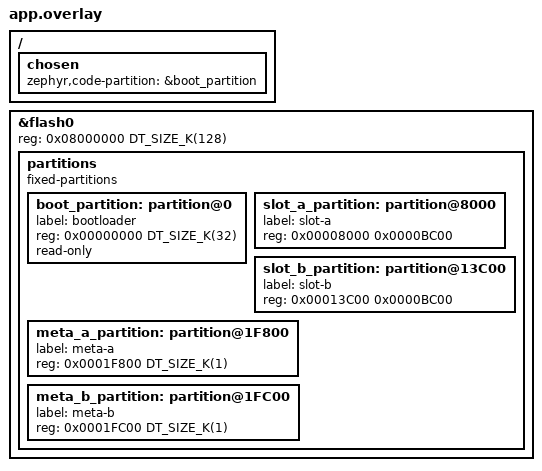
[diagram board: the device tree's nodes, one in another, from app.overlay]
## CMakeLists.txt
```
cmake_minimum_required(VERSION 3.20.0)

find_package(Zephyr REQUIRED HINTS $ENV{ZEPHYR_BASE})
project(f103_usb_bootloader)

target_sources(app PRIVATE
  src/main.c
  src/flash_update.c
  common/f103_bootloader_api.c
)

target_include_directories(app PRIVATE
  include
  src
  common
)
```

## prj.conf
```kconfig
CONFIG_MAIN_STACK_SIZE=2048
CONFIG_SYSTEM_WORKQUEUE_STACK_SIZE=2048

CONFIG_LOG=n
CONFIG_PRINTK=n
CONFIG_BOOT_BANNER=n
CONFIG_CONSOLE=n
CONFIG_UART_CONSOLE=n
CONFIG_SERIAL=n
CONFIG_ASSERT=n
CONFIG_REBOOT=y

CONFIG_FLASH=y
CONFIG_FLASH_PAGE_LAYOUT=y
CONFIG_CRC=y
CONFIG_USE_DT_CODE_PARTITION=y

# The current USB Device stack is required on STM32F103 because its USB
# peripheral is not supported by the UDC-based stack.
CONFIG_USB_DEVICE_STACK=y
CONFIG_USB_DEVICE_STACK_NEXT=n
CONFIG_USB_DEVICE_HID=y
CONFIG_ENABLE_HID_INT_OUT_EP=y
CONFIG_HID_INTERRUPT_EP_MPS=64
CONFIG_USB_HID_POLL_INTERVAL_MS=1
CONFIG_USB_DEVICE_VID=0x1209
CONFIG_USB_DEVICE_PID=0xF103
CONFIG_USB_DEVICE_MANUFACTURER="F103 Open Project"
CONFIG_USB_DEVICE_PRODUCT="F103 USB IAP Bootloader"
CONFIG_USB_DEVICE_SN="F103-IAP-0001"
CONFIG_USB_DC_STM32_CLOCK_CHECK=n

# This project intentionally uses the deprecated device stack. Zephyr 4.4
# still provides it for STM32F1; keep the warning noise out of the build.
CONFIG_DEPRECATION_TEST=n
CONFIG_WARN_DEPRECATED=n
```

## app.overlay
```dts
/*
 * STM32F103CBT6: 128 KiB flash, 20 KiB SRAM.
 *
 * 0x08000000 - 0x08007FFF  bootloader (32 KiB)
 * 0x08008000 - 0x08013BFF  application slot A (47 KiB)
 * 0x08013C00 - 0x0801F7FF  application slot B (47 KiB)
 * 0x0801F800 - 0x0801FBFF  metadata page A (1 KiB)
 * 0x0801FC00 - 0x0801FFFF  metadata page B (1 KiB)
 */

&flash0 {
	reg = <0x08000000 DT_SIZE_K(128)>;

	partitions {
		compatible = "fixed-partitions";
		#address-cells = <1>;
		#size-cells = <1>;

		boot_partition: partition@0 {
			label = "bootloader";
			reg = <0x00000000 DT_SIZE_K(32)>;
			read-only;
		};

		slot_a_partition: partition@8000 {
			label = "slot-a";
			reg = <0x00008000 0x0000BC00>;
		};

		slot_b_partition: partition@13C00 {
			label = "slot-b";
			reg = <0x00013C00 0x0000BC00>;
		};

		meta_a_partition: partition@1F800 {
			label = "meta-a";
			reg = <0x0001F800 DT_SIZE_K(1)>;
		};

		meta_b_partition: partition@1FC00 {
			label = "meta-b";
			reg = <0x0001FC00 DT_SIZE_K(1)>;
		};
	};
};

/ {
	chosen {
		zephyr,code-partition = &boot_partition;
	};
};
```

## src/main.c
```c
/*
 * USB HID IAP bootloader for STM32F103CBT6.
 *
 * SPDX-License-Identifier: Apache-2.0
 */

#include "f103_bootloader_api.h"
#include "f103_hid_descriptor.h"
#include "f103_iap.h"
#include "flash_update.h"

#include <string.h>

#include <stm32f1xx.h>
#include <zephyr/device.h>
#include <zephyr/kernel.h>
#include <zephyr/sys/byteorder.h>
#include <zephyr/usb/class/usb_hid.h>
#include <zephyr/usb/usb_device.h>

#define BOOT_WINDOW_MS       3000
#define CONFIG_WINDOW_MS     2500
#define IAP_THREAD_STACK     2048
#define IAP_THREAD_PRIORITY  4

struct hid_message {
	uint8_t data[F103_HID_REPORT_SIZE];
	uint32_t length;
};

K_MSGQ_DEFINE(hid_rx_queue, sizeof(struct hid_message), 2, 4);
K_SEM_DEFINE(hid_tx_done, 0, 1);

static const struct device *hid_device;
static volatile bool upgrade_session;
static volatile bool run_requested;
static volatile bool image_committed;
static int64_t boot_deadline;

/*
 * Most STM32F103 boards have a permanently connected 1.5 kOhm pull-up on
 * USB D+. Pull D+ low while the application runs so the host sees a real
 * disconnect. Reset restores PA12 to its input state and reattaches USB.
 */
static void usb_disconnect_dp(void)
{
	RCC->APB2ENR |= RCC_APB2ENR_IOPAEN;
	(void)RCC->APB2ENR;

	/* PA12: output push-pull, 2 MHz, then drive low. */
	GPIOA->CRH = (GPIOA->CRH & ~(0xFU << 16)) | (0x2U << 16);
	GPIOA->BSRR = GPIO_BSRR_BR12;
	__DSB();
}

static void jump_to_application(uint32_t base)
{
	__disable_irq();

	SysTick->CTRL = 0U;
	SysTick->LOAD = 0U;
	SysTick->VAL = 0U;

	for (uint32_t i = 0U; i < (sizeof(NVIC->ICER) / sizeof(NVIC->ICER[0])); i++) {
		NVIC->ICER[i] = 0xFFFFFFFFU;
		NVIC->ICPR[i] = 0xFFFFFFFFU;
	}

	SCB->VTOR = base;
	__DSB();
	__ISB();

	/*
	 * The register write, MSP switch and branch are deliberately one asm
	 * sequence. After switching MSP, this function must not touch its own
	 * bootloader stack again.
	 */
	__asm volatile(
		"ldr r1, [%[base]]\n\t"
		"ldr r2, [%[base], #4]\n\t"
		"movs r3, #0\n\t"
		"msr control, r3\n\t"
		"isb\n\t"
		"msr msp, r1\n\t"
		"msr basepri, r3\n\t"
		"cpsie f\n\t"
		"cpsie i\n\t"
		"isb\n\t"
		"bx r2\n\t"
		:
		: [base] "r" (base)
		: "r1", "r2", "r3", "memory");

	__builtin_unreachable();
}

/*
 * Jump into the STM32 factory system-memory bootloader (USB DFU). This is
 * the field recovery path for updating the bootloader itself without SWD:
 * the factory DFU is resident in ROM and cannot be bricked by our code.
 */
#define F103_SYSTEM_MEMORY 0x1FFFF000U

static void jump_to_system_dfu(void)
{
	__disable_irq();

	SysTick->CTRL = 0U;
	SysTick->LOAD = 0U;
	SysTick->VAL = 0U;

	for (uint32_t i = 0U; i < (sizeof(NVIC->ICER) / sizeof(NVIC->ICER[0])); i++) {
		NVIC->ICER[i] = 0xFFFFFFFFU;
		NVIC->ICPR[i] = 0xFFFFFFFFU;
	}

	__DSB();
	__ISB();

	const uint32_t sp = *(volatile const uint32_t *)F103_SYSTEM_MEMORY;
	const uint32_t pc = *(volatile const uint32_t *)(F103_SYSTEM_MEMORY + 4U);

	__asm volatile(
		"msr msp, %[sp]\n\t"
		"bx %[pc]\n\t"
		:
		: [sp] "r" (sp), [pc] "r" (pc)
		: "memory");

	__builtin_unreachable();
}

static int send_report(const uint8_t *report, size_t length)
{
	uint32_t written = 0U;

	k_sem_reset(&hid_tx_done);

	const int err = hid_int_ep_write(hid_device, report, length, &written);
	if (err < 0) {
		return err;
	}

	if (k_sem_take(&hid_tx_done, K_MSEC(1000)) != 0) {
		return -ETIMEDOUT;
	}

	return written == length ? 0 : -EIO;
}

static int send_response(uint8_t command, uint8_t sequence, uint8_t status,
			 uint32_t value, const uint8_t *extra, size_t extra_len)
{
	uint8_t report[F103_HID_REPORT_SIZE] = {0U};

	report[0] = F103_HID_REPORT_ID_IN;
	report[1] = status;
	report[2] = command;
	report[3] = sequence;
	sys_put_le32(value, &report[4]);
	if (extra != NULL) {
		extra_len = MIN(extra_len, sizeof(report) - 8U);
		memcpy(&report[8], extra, extra_len);
	}

	return send_report(report, sizeof(report));
}

static void process_request(const uint8_t *request, size_t length)
{
	uint8_t sequence;
	uint8_t command;
	uint8_t data_length;
	uint32_t address;
	const uint8_t *data;
	uint8_t status = F103_IAP_OK;
	uint32_t value = 0U;
	uint8_t extra[30] = {0U};
	bool run_after_response = false;
	bool dfu_after_response = false;
	int err = 0;

	if (length > 0U && request[0] == F103_HID_REPORT_ID_OUT) {
		request++;
		length--;
	}

	if (length < F103_IAP_HEADER_SIZE ||
	    request[0] != F103_IAP_MAGIC0 ||
	    request[1] != F103_IAP_MAGIC1) {
		return;
	}

	command = request[2];
	sequence = request[3];
	address = sys_get_le32(&request[4]);
	data_length = request[8];
	data = &request[F103_IAP_HEADER_SIZE];

	if (data_length > F103_HID_DATA_MAX ||
	    (size_t)data_length > length - F103_IAP_HEADER_SIZE) {
		status = F103_IAP_ERR_ARG;
		goto respond;
	}

	switch (command) {
	case F103_IAP_PING:
		{
			const int active_slot = flash_update_active_slot();
			const int target_slot = flash_update_target_slot();

			value = F103_IAP_VERSION;
			sys_put_le32(flash_update_slot_base(active_slot), &extra[0]);
			sys_put_le32(flash_update_slot_base(target_slot), &extra[4]);
			sys_put_le32(flash_update_slot_size(), &extra[8]);
			extra[12] = F103_IAP_ROLE_BOOTLOADER;
			extra[13] = (uint8_t)MAX(active_slot, 0);
			extra[14] = (uint8_t)MAX(target_slot, 0);
			extra[15] = active_slot >= 0 ? 1U : 0U;

			{
				uint8_t pending = 0U;
				uint8_t attempts = 0U;
				uint8_t known_good = 0U;
				uint8_t swap_busy = 0U;
				uint8_t swap_done = 0U;
				uint8_t swap_total = 0U;

				(void)flash_update_test_state(&pending, &attempts,
							      &known_good, &swap_busy,
							      &swap_done, &swap_total);
				extra[16] = pending;
				extra[17] = attempts;
				extra[18] = F103_TEST_BOOT_MAX_ATTEMPTS;
				extra[19] = known_good;
				extra[20] = swap_busy;
				extra[21] = swap_done;
				extra[22] = swap_total;

				{
					uint32_t fw_version = 0U;
					uint8_t fw_build = 0U;

					if (flash_update_read_app_version(
							&fw_version, &fw_build)) {
						sys_put_le32(fw_version, &extra[24]);
						extra[28] = fw_build;
						extra[29] = 1U;
					}
				}
			}
		}
		break;

	case F103_IAP_BEGIN:
		/*
		 * Only a real download session may keep the bootloader in its
		 * USB window. A passively polling host (PING) must not prevent
		 * the automatic jump to the application.
		 */
		upgrade_session = true;
		err = flash_update_begin(address);
		if (err == -EINVAL) {
			status = F103_IAP_ERR_ARG;
		} else if (err < 0) {
			status = F103_IAP_ERR_FLASH;
		}
		break;

	case F103_IAP_DATA:
		if (address > F103_SLOT_SIZE ||
		    data_length > F103_SLOT_SIZE - address) {
			status = F103_IAP_ERR_RANGE;
			break;
		}

		err = flash_update_write(address, data, data_length);
		if (err == -ERANGE || err == -EINVAL) {
			status = F103_IAP_ERR_RANGE;
		} else if (err < 0) {
			status = F103_IAP_ERR_FLASH;
		}
		break;

	case F103_IAP_END: {
		uint32_t actual_crc = 0U;

		err = flash_update_finish(address, &actual_crc);
		image_committed = (err == 0);
		value = actual_crc;
		if (err == -EILSEQ) {
			status = F103_IAP_ERR_CRC;
		} else if (err == -EIO) {
			status = F103_IAP_ERR_FLASH;
		} else if (err == -EINVAL) {
			/* no active session / incomplete download */
			status = F103_IAP_ERR_STATE;
		} else if (err < 0) {
			status = F103_IAP_ERR_IMAGE;
		}
		break;
	}

	case F103_IAP_RUN:
		if (!flash_update_image_valid(true)) {
			status = F103_IAP_ERR_IMAGE;
		} else {
			run_after_response = true;
		}
		break;

	case F103_IAP_ENTER_ROM_BOOTLOADER:
		dfu_after_response = true;
		break;

	default:
		status = F103_IAP_ERR_COMMAND;
		break;
	}

respond:
	err = send_response(command, sequence, status, value, extra, sizeof(extra));
	if (err == 0 && run_after_response) {
		run_requested = true;
	}
	if (err == 0 && dfu_after_response) {
		k_sleep(K_MSEC(100));
		(void)usb_disable();
		/* Force a real disconnect so the host enumerates the ROM DFU. */
		usb_disconnect_dp();
		k_sleep(K_MSEC(500));
		jump_to_system_dfu();
	}
}

static void iap_thread(void *p1, void *p2, void *p3)
{
	struct hid_message message;

	ARG_UNUSED(p1);
	ARG_UNUSED(p2);
	ARG_UNUSED(p3);

	while (true) {
		if (k_msgq_get(&hid_rx_queue, &message, K_FOREVER) == 0) {
			process_request(message.data, message.length);
		}
	}
}

K_THREAD_DEFINE(iap_thread_id, IAP_THREAD_STACK, iap_thread, NULL, NULL, NULL,
		IAP_THREAD_PRIORITY, 0, 0);

static void hid_int_in_ready_cb(const struct device *dev)
{
	ARG_UNUSED(dev);
	k_sem_give(&hid_tx_done);
}

static void hid_int_out_ready_cb(const struct device *dev)
{
	struct hid_message message;
	uint32_t received = 0U;
	int err;

	err = hid_int_ep_read(dev, message.data, sizeof(message.data), &received);
	if (err < 0 || received == 0U) {
		return;
	}

	message.length = received;
	(void)k_msgq_put(&hid_rx_queue, &message, K_NO_WAIT);
}

static const struct hid_ops hid_ops = {
	.int_in_ready = hid_int_in_ready_cb,
	.int_out_ready = hid_int_out_ready_cb,
};

static void usb_status_cb(enum usb_dc_status_code status, const uint8_t *param)
{
	ARG_UNUSED(param);

	if (status == USB_DC_CONFIGURED) {
		const int64_t now = k_uptime_get();

		if (boot_deadline < now + CONFIG_WINDOW_MS) {
			boot_deadline = now + CONFIG_WINDOW_MS;
		}
	}
}

static int init_usb(void)
{
	hid_device = device_get_binding("HID_0");
	if (hid_device == NULL) {
		return -ENODEV;
	}

	usb_hid_register_device(hid_device, f103_hid_report_descriptor,
				sizeof(f103_hid_report_descriptor), &hid_ops);
	usb_hid_init(hid_device);

	return usb_enable(usb_status_cb);
}

int main(void)
{
	const bool force_bootloader = f103_bootloader_consume_request();
	uint32_t boot_base = 0U;
	const bool image_valid = flash_update_get_boot_info(&boot_base, true);
	int err;

	boot_deadline = k_uptime_get() + BOOT_WINDOW_MS;

	err = init_usb();
	if (err < 0) {
		if (image_valid && !force_bootloader) {
			usb_disconnect_dp();
			jump_to_application(boot_base);
		}

		while (true) {
			k_sleep(K_FOREVER);
		}
	}

	while (true) {
		if (run_requested) {
			/*
			 * A pending record downloaded during this session counts
			 * its first TEST boot here. Otherwise the boot decision
			 * was already made once at startup.
			 */
			const bool can_boot = image_committed
				? flash_update_get_boot_info(&boot_base, true)
				: (boot_base != 0U &&
				   flash_update_image_valid(true));

			if (can_boot) {
				(void)usb_disable();
				k_sleep(K_MSEC(100));
				usb_disconnect_dp();
				jump_to_application(boot_base);
			}

			run_requested = false;
		}

		if (!force_bootloader && image_valid && !upgrade_session &&
		    !run_requested && k_uptime_get() >= boot_deadline) {
			(void)usb_disable();
			k_sleep(K_MSEC(50));
			usb_disconnect_dp();
			jump_to_application(boot_base);
		}

		k_sleep(K_MSEC(20));
	}
}
```

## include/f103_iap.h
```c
/*
 * Shared layout and USB HID IAP protocol for the F103 bootloader.
 *
 * MCUboot-style layout: firmware is always downloaded into slot B and
 * swapped sector-by-sector into slot A (the boot slot) before the test
 * boot. A scratch sector and a persistent swap log make the exchange
 * power-loss safe.
 *
 * SPDX-License-Identifier: Apache-2.0
 */

#ifndef F103_IAP_H_
#define F103_IAP_H_

#include <stdint.h>

#define F103_FLASH_BASE         0x08000000U
#define F103_BOOT_SIZE          (32U * 1024U)
#define F103_SLOT_A_BASE        0x08008000U
#define F103_SLOT_B_BASE        0x08013C00U
#define F103_SLOT_SIZE          (46U * 1024U)
#define F103_FLASH_END          0x08020000U
#define F103_FLASH_PAGE_SIZE    1024U

#define F103_BOOT_OFFSET        0x00000000U
#define F103_SLOT_A_OFFSET      0x00008000U
#define F103_SCRATCH_OFFSET     0x00013800U
#define F103_SLOT_B_OFFSET      0x00013C00U
#define F103_SWAP_LOG_OFFSET    0x0001F400U
#define F103_META_A_OFFSET      0x0001F800U
#define F103_META_B_OFFSET      0x0001FC00U
#define F103_META_PAGE_SIZE     (1U * 1024U)

/*
 * v3 metadata ("3BMT"): MCUboot-style flow. Images are single-linked for
 * slot A; slot B is only a download slot. flags carry the pending TEST
 * state and the sector-swap request. v1/v2 records are invalid.
 */
#define F103_META_MAGIC         0x544D4233U /* "3BMT" */
#define F103_SLOT_VALID         0x56414C44U /* "DALV" */
#define F103_BOOT_REQUEST_MAGIC 0xB007F103U
#define F103_IAP_VERSION        0x00030000U

/* Metadata flags. */
#define F103_META_FLAG_PENDING  0x00000001U /* tested image awaits image_ok */
#define F103_META_FLAG_SWAP     0x00000002U /* A/B sector exchange requested */

/* Test boots allowed before the bootloader swaps back to the known-good. */
#define F103_TEST_BOOT_MAX_ATTEMPTS 3U

#define F103_HID_REPORT_ID_IN   0x01U
#define F103_HID_REPORT_ID_OUT  0x02U
#define F103_HID_REPORT_SIZE    64U
#define F103_IAP_HEADER_SIZE    9U
#define F103_HID_DATA_MAX       (F103_HID_REPORT_SIZE - 1U - F103_IAP_HEADER_SIZE)

#define F103_IAP_MAGIC0         0xA5U
#define F103_IAP_MAGIC1         0x5AU

enum f103_iap_cmd {
	F103_IAP_PING = 1,
	F103_IAP_BEGIN = 2,
	F103_IAP_DATA = 3,
	F103_IAP_END = 4,
	F103_IAP_RUN = 5,
	F103_IAP_ENTER_BOOTLOADER = 6,
	F103_IAP_ENTER_ROM_BOOTLOADER = 7,
};

enum f103_iap_role {
	F103_IAP_ROLE_BOOTLOADER = 1,
	F103_IAP_ROLE_APPLICATION = 2,
};

enum f103_iap_status {
	F103_IAP_OK = 0,
	F103_IAP_ERR_ARG = 1,
	F103_IAP_ERR_STATE = 2,
	F103_IAP_ERR_RANGE = 3,
	F103_IAP_ERR_FLASH = 4,
	F103_IAP_ERR_CRC = 5,
	F103_IAP_ERR_IMAGE = 6,
	F103_IAP_ERR_COMMAND = 7,
};

struct f103_slot_meta {
	uint32_t start;
	uint32_t size;
	uint32_t crc32;
	uint32_t state;
};

struct f103_meta {
	uint32_t magic;
	uint32_t sequence;
	uint32_t active_slot;
	uint32_t known_good_slot;
	uint32_t boot_attempts;
	uint32_t flags;
	struct f103_slot_meta slot[2];
	uint32_t record_crc;
};

#endif /* F103_IAP_H_ */
```

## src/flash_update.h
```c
/*
 * Flash update backend for the F103 USB bootloader.
 *
 * SPDX-License-Identifier: Apache-2.0
 */

#ifndef FLASH_UPDATE_H_
#define FLASH_UPDATE_H_

#include <stdbool.h>
#include <stddef.h>
#include <stdint.h>

int flash_update_begin(uint32_t image_size);
int flash_update_write(uint32_t offset, const uint8_t *data, size_t len);
int flash_update_finish(uint32_t expected_crc, uint32_t *actual_crc);

bool flash_update_image_valid(bool verify_crc);
bool flash_update_get_boot_info(uint32_t *base, bool verify_crc);
int flash_update_active_slot(void);
int flash_update_target_slot(void);
uint32_t flash_update_slot_base(int slot);
uint32_t flash_update_slot_size(void);

/*
 * Read the firmware version block embedded in the slot A image.
 * Returns false when no metadata / no version block is present.
 */
bool flash_update_read_app_version(uint32_t *version, uint8_t *build);

/* Pending TEST / swap state of the latest metadata record. */
bool flash_update_test_state(uint8_t *pending, uint8_t *attempts,
                             uint8_t *known_good_slot, uint8_t *swap_busy,
                             uint8_t *swap_done, uint8_t *swap_total);

/*
 * Called by the running application after its self-test passed: clears the
 * pending flag (writes image_ok) and makes the tested image permanent.
 */
int flash_update_confirm_image(void);

#endif /* FLASH_UPDATE_H_ */
```
